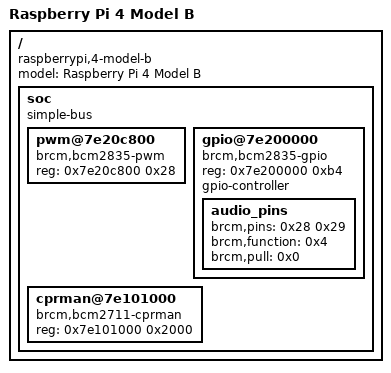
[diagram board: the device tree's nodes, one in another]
// SPDX-License-Identifier: BSD-3-Clause
// Copyright (c) 2026, Bo Maryniuk and RavenBSD contributors
// Generated by tests/fixtures/pi4-audio/generate.py; fixture pi4-audio.
/dts-v1/;

/ {
    compatible = "raspberrypi,4-model-b", "brcm,bcm2711";
    model = "Raspberry Pi 4 Model B";
    #address-cells = <0x2>;
    #size-cells = <0x2>;
    soc {
        compatible = "simple-bus";
        #address-cells = <0x1>;
        #size-cells = <0x1>;
        ranges = <0x7e000000 0x0 0xfe000000 0x1800000>;
        pwm@7e20c800 {
            compatible = "brcm,bcm2835-pwm";
            reg = <0x7e20c800 0x28>;
            status = "okay";
        };
        gpio@7e200000 {
            compatible = "brcm,bcm2835-gpio";
            reg = <0x7e200000 0xb4>;
            #gpio-cells = <0x2>;
            status = "okay";
            gpio-controller;
            audio_pins {
                brcm,pins = <0x28 0x29>;
                brcm,function = <0x4>;
                brcm,pull = <0x0>;
            };
        };
        cprman@7e101000 {
            compatible = "brcm,bcm2711-cprman";
            reg = <0x7e101000 0x2000>;
            #clock-cells = <0x1>;
            status = "okay";
        };
    };
};
